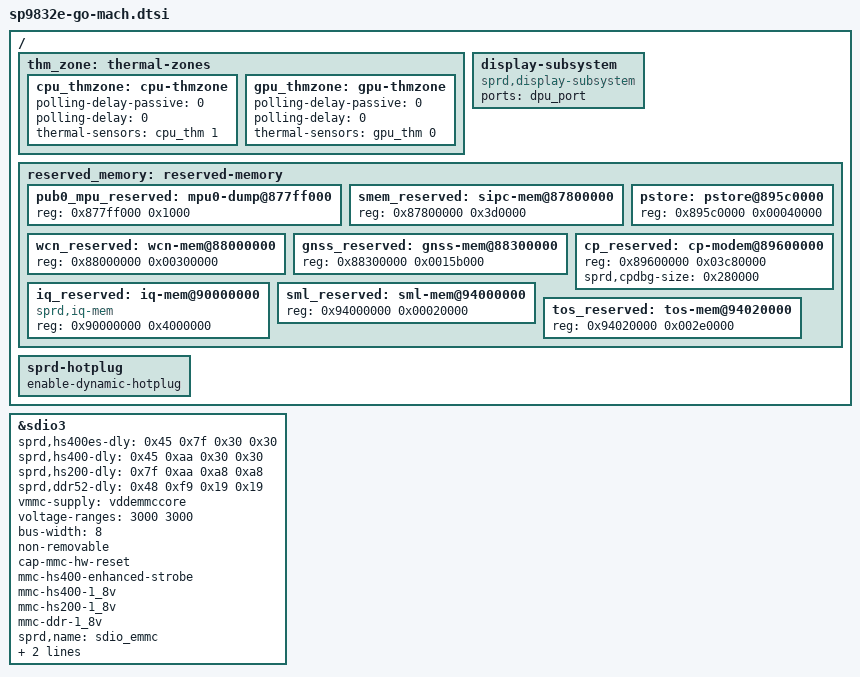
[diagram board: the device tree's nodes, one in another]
/*
 * Spreadtrum SP98x0 board common DTS file
 *
 * Copyright (C) 2019, Spreadtrum Communications Inc.
 *
 * This file is licensed under a dual GPLv2 or X11 license.
 */

/ {

	thm_zone: thermal-zones {

		cpu_thmzone: cpu-thmzone {
			polling-delay-passive = <0>;
			polling-delay = <0>;
			thermal-sensors = <&cpu_thm 1>;
		};

		gpu_thmzone: gpu-thmzone {
			polling-delay-passive = <0>;
			polling-delay = <0>;
			thermal-sensors = <&gpu_thm 0>;
		};
	};

	display-subsystem {
		compatible = "sprd,display-subsystem";
		ports = <&dpu_port>;
		/*gsp = <&gsp>;*/
	};

	reserved_memory: reserved-memory {
		#address-cells = <1>;
		#size-cells = <1>;
		ranges;

		pub0_mpu_reserved: mpu0-dump@877ff000 {
			reg = <0x877ff000 0x1000>;
		};

		smem_reserved: sipc-mem@87800000 {
			reg = <0x87800000 0x3d0000>;
		};

		/* must be 32M aligned */
		wcn_reserved: wcn-mem@88000000 {
			reg = <0x88000000 0x00300000>;
		};

		gnss_reserved: gnss-mem@88300000 {
			reg = <0x88300000 0x0015b000>;
		};

		pstore: pstore@895c0000 {
			reg = <0x895c0000 0x00040000>;
		};

		/* cp_reserved = cp region + debug region */
		/* debug region: not reserved in normal mode, it */
		/* will be proccessed in u-boot */
		cp_reserved: cp-modem@89600000 {
			reg = <0x89600000 0x03c80000>;
			/* This prop specifies the size of debug region */
			/* in the cp tail */
			sprd,cpdbg-size = <0x280000>;
		};

		/* Only used for iq, will be removed in normal mode by uboot */
		iq_reserved: iq-mem@90000000 {
			compatible = "sprd,iq-mem";
			reg = <0x90000000 0x4000000>;
		};

		/* must be 64M aligned */
		sml_reserved: sml-mem@94000000 {
			reg = <0x94000000 0x00020000>;
		};

		tos_reserved: tos-mem@94020000 {
			reg = <0x94020000 0x002e0000>;
		};
	};
	sprd-hotplug {
		enable-dynamic-hotplug;
	};
};

&sdio3 {
	sprd,hs400es-dly = <0x45 0x7f 0x30 0x30>;
	sprd,hs400-dly = <0x45 0xaa 0x30 0x30>;
	sprd,hs200-dly = <0x7f 0xaa 0xa8 0xa8>;
	sprd,ddr52-dly = <0x48 0xf9 0x19 0x19>;
	vmmc-supply = <&vddemmccore>;
	voltage-ranges = <3000 3000>;
	bus-width = <8>;
	non-removable;
	cap-mmc-hw-reset;
	mmc-hs400-enhanced-strobe;
	mmc-hs400-1_8v;
	mmc-hs200-1_8v;
	mmc-ddr-1_8v;
	sprd,name = "sdio_emmc";
	no-sdio;
	no-sd;
	status = "okay";
};
